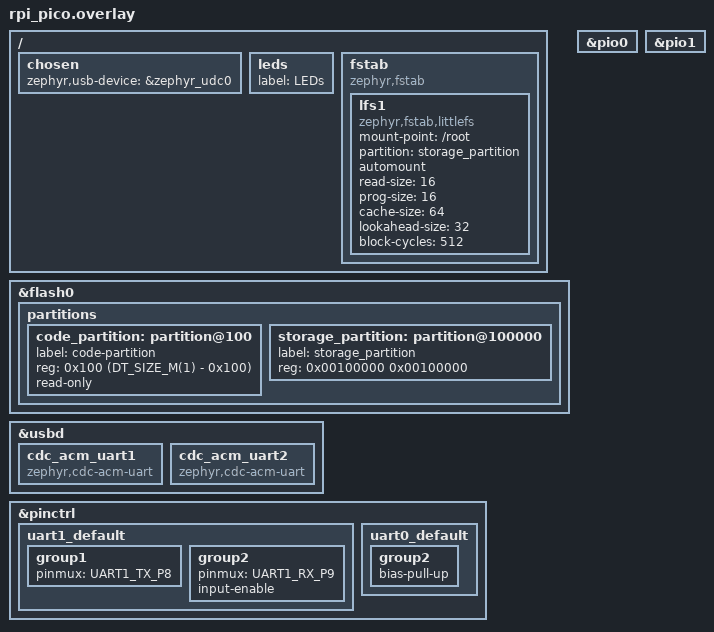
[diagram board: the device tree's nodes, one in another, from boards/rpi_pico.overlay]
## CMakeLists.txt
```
# SPDX-License-Identifier: Apache-2.0

cmake_minimum_required(VERSION 3.20.0)
find_package(Zephyr REQUIRED HINTS $ENV{ZEPHYR_BASE})
project(AllinOneHub)

# target_sources(app PRIVATE boards/gpio_level_raytac_mbt50q_db_40_nrf52840.c)

add_subdirectory(src)
add_subdirectory(lib)
```

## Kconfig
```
# Copyright (c) 2019 Peter Bigot Consulting, LLC
# SPDX-License-Identifier: Apache-2.0

mainmenu "Flower Vending Machine"

config HUB_OFF_TIMEOUT
	int "USB hub off timeout"
	default 1200
	help
	    Timeout to turn off hub power when there is no ping (Unit: seconds)

config HUB_POWER_LED_BLANK_TIME
    int "USB hub power led blank time"
    default 500
    help
        USB hub power led blank time when loss ping (Unit: milliseconds)

config PING_LOSS_DECISION_TIMEOUT
    int "Ping loss decision timeout"
    default 3
    help
        Ping loss decision timeout (Unit: seconds)

config POWER_OFF_SETTING_TIMEOUT
    int "power off setting timeout"
    default 3
    help
        Timeout that automatically comes out of the setting mode 
        when there is no operation when setting the power off schedule
        (Unit: seconds)

rsource "src/Kconfig"
```

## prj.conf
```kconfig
CONFIG_GPIO=y

CONFIG_USB_DEVICE_STACK=y
CONFIG_USB_DEVICE_INITIALIZE_AT_BOOT=n
```

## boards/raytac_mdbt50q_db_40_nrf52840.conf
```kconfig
CONFIG_USB_COMPOSITE_DEVICE=y

# CONFIG_USB_DEVICE_PRODUCT="Zephyr HID and CDC ACM sample"
# CONFIG_USB_DEVICE_PID=0x0003

CONFIG_ENTROPY_GENERATOR=y
CONFIG_ENTROPY_DEVICE_RANDOM_GENERATOR=y

# CONFIG_USB_DEVICE_INITIALIZE_AT_BOOT=n
CONFIG_LOG=y
CONFIG_USB_DRIVER_LOG_LEVEL_INF=y
CONFIG_USB_DEVICE_LOG_LEVEL_INF=y
CONFIG_USB_CDC_ACM_LOG_LEVEL_OFF=y

CONFIG_SERIAL=y
CONFIG_UART_LINE_CTRL=y

# Logging Setting
CONFIG_LOG=y
CONFIG_LOG_BACKEND_UART=y
CONFIG_LOG_BUFFER_SIZE=2048
# CONFIG_LOG_PROCESS_THREAD_STACK_SIZE=4096

# Enable Shell
CONFIG_SHELL=y
CONFIG_SHELL_BACKEND_SERIAL=y
CONFIG_SHELL_LOG_BACKEND=n
CONFIG_SHELL_STACK_SIZE=3168
CONFIG_FILE_SYSTEM_SHELL=y

CONFIG_SYSTEM_WORKQUEUE_STACK_SIZE=4096

# Enable REBOOT
CONFIG_REBOOT=y

# Enable Posix Api
CONFIG_POSIX_API=y
CONFIG_POSIX_FS=y

# Enable c++
CONFIG_CPLUSPLUS=y
CONFIG_CPP_MAIN=y
CONFIG_LIB_CPLUSPLUS=y
# CONFIG_LIBCPP_IMPLEMENTATION=y
CONFIG_HEAP_MEM_POOL_SIZE=10240

CONFIG_MAIN_STACK_SIZE=4096

# Enable I2C
CONFIG_I2C=y

# Enable LED api
CONFIG_LED=y
CONFIG_LED_SHELL=y
```

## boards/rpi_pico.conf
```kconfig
CONFIG_USB_DEVICE_STACK=y
CONFIG_USB_DEVICE_INITIALIZE_AT_BOOT=n
CONFIG_USB_COMPOSITE_DEVICE=y
CONFIG_USB_DEVICE_MANUFACTURER="Superfect"
CONFIG_USB_DEVICE_PRODUCT="AllinOne Monitor Stand"
CONFIG_USB_DEVICE_VID=0x4321
CONFIG_USB_DEVICE_PID=0x0001
CONFIG_USB_DEVICE_REMOTE_WAKEUP=y
CONFIG_USB_DEVICE_HID=y
CONFIG_USB_HID_DEVICE_COUNT=1


# CONFIG_USB_DEVICE_INITIALIZE_AT_BOOT=n
# CONFIG_USB_DRIVER_LOG_LEVEL_INF=y
# CONFIG_USB_DEVICE_LOG_LEVEL_INF=y
# CONFIG_USB_CDC_ACM_LOG_LEVEL_DBG=y
# CONFIG_USB_CDC_ACM_LOG_LEVEL_OFF=y

CONFIG_SERIAL=y
CONFIG_UART_LINE_CTRL=y

# Logging Setting
CONFIG_LOG=y
CONFIG_LOG_BACKEND_UART=y
CONFIG_LOG_BUFFER_SIZE=2048
# CONFIG_LOG_PROCESS_THREAD_STACK_SIZE=4096

# Enable Shell
CONFIG_SHELL=y
CONFIG_SHELL_BACKEND_SERIAL=y
CONFIG_SHELL_BACKEND_DUMMY=y
CONFIG_SHELL_LOG_BACKEND=n
CONFIG_SHELL_STACK_SIZE=3168
CONFIG_FILE_SYSTEM_SHELL=y

CONFIG_SYSTEM_WORKQUEUE_STACK_SIZE=4096

# Enable REBOOT
CONFIG_REBOOT=y

# Enable Flash
CONFIG_FLASH=y
CONFIG_FLASH_MAP=y
CONFIG_FLASH_PAGE_LAYOUT=y
CONFIG_FILE_SYSTEM=y
CONFIG_FILE_SYSTEM_LITTLEFS=y

# Enable Posix Api
CONFIG_POSIX_API=y
CONFIG_POSIX_FS=y

# Enable c++
CONFIG_CPLUSPLUS=y
CONFIG_CPP_MAIN=y
CONFIG_LIB_CPLUSPLUS=y
# CONFIG_LIBCPP_IMPLEMENTATION=y
CONFIG_HEAP_MEM_POOL_SIZE=10240

CONFIG_MAIN_STACK_SIZE=4096

# # Enable I2C
# CONFIG_I2C=y

# Enable LED api
CONFIG_LED=y
CONFIG_LED_SHELL=y

# Enable pio
CONFIG_PIO_RPI_PICO=y

# # Chagnge shell priority
# CONFIG_SHELL_THREAD_PRIORITY_OVERRIDE=y
# CONFIG_SHELL_THREAD_PRIORITY=10

# # Thread analyzer
# CONFIG_THREAD_ANALYZER=y
# CONFIG_THREAD_ANALYZER_AUTO=y

CONFIG_DEBUG_INFO=y
CONFIG_DEBUG_COREDUMP=y
CONFIG_DEBUG_COREDUMP_BACKEND_LOGGING=y
```

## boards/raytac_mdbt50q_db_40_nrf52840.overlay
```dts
/*
 * Copyright (c) 2021 Nordic Semiconductor ASA
 *
 * SPDX-License-Identifier: Apache-2.0
 */

// /delete-node/ &uart1;
// /delete-node/ &uart1_default;
// /delete-node/ &uart1_sleep;

/delete-node/ &i2c1;
/delete-node/ &i2c1_default;
/delete-node/ &i2c1_sleep;

// /delete-node/ &pwm_led0;
// /delete-node/ &pwm0;
// /delete-node/ &pwm0_default;
// /delete-node/ &pwm0_sleep;

/delete-node/ &spi0;
/delete-node/ &spi0_default;
/delete-node/ &spi0_sleep;

/delete-node/ &spi1;
/delete-node/ &spi1_default;
/delete-node/ &spi1_sleep;

/delete-node/ &spi2;
/delete-node/ &spi2_default;
/delete-node/ &spi2_sleep;

/delete-node/ &qspi;
/delete-node/ &qspi_default;
/delete-node/ &qspi_sleep;


/ {
	chosen {
		zephyr,console = &cdc_acm_uart0;
		zephyr,shell-uart = &cdc_acm_uart0;
		zephyr,uart-mcumgr = &cdc_acm_uart0;
		zephyr,bt-mon-uart = &cdc_acm_uart0;
		zephyr,bt-c2h-uart = &cdc_acm_uart0;
        zephyr,usb-device = &zephyr_udc0;
	};

	leds: leds {
		label = "LEDs";
	};
};

&i2c0 {
	clock-frequency = <I2C_BITRATE_STANDARD>;
};

zephyr_udc0: &usbd {
	cdc_acm_uart0: cdc_acm_uart0 {
		compatible = "zephyr,cdc-acm-uart";
	};

	cdc_acm_uart1: cdc_acm_uart1 {
		compatible = "zephyr,cdc-acm-uart";
	};

	// cdc_acm_uart2: cdc_acm_uart2 {
	// 	compatible = "zephyr,cdc-acm-uart";
	// };
};

&pinctrl {
	// i2c0_default: i2c0_default {
	// 	group1 {
	// 		psels = <NRF_PSEL(TWIM_SDA, 0, 22)>,
	// 			<NRF_PSEL(TWIM_SCL, 0, 24)>;
	// 	};
	// };

	// i2c0_sleep: i2c0_sleep {
	// 	group1 {
	// 		psels = <NRF_PSEL(TWIM_SDA, 0, 22)>,
	// 			<NRF_PSEL(TWIM_SCL, 0, 24)>;
	// 		low-power-enable;
	// 	};
	// };
};
```

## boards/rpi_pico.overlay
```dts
/delete-node/ &i2c0;
/delete-node/ &i2c0_default;

/delete-node/ &spi0;
/delete-node/ &spi0_default;

/ {
	chosen {
		// zephyr,console = &cdc_acm_uart0;
		// zephyr,shell-uart = &cdc_acm_uart0;
        zephyr,usb-device = &zephyr_udc0;
	};

	leds: leds {
		label = "LEDs";
	};

	fstab {
		compatible = "zephyr,fstab";
		lfs1: lfs1 {
			compatible = "zephyr,fstab,littlefs";
			mount-point = "/root";
			partition = <&storage_partition>;
			automount;
			read-size = <16>;
			prog-size = <16>;
			cache-size = <64>;
			lookahead-size = <32>;
			block-cycles = <512>;
		};
	};
};

// &uart1 {
// 	current-speed = <9600>;
// 	status = "okay";
// 	pinctrl-0 = <&uart1_default>;
// 	pinctrl-names = "default";
// };

&flash0 {

	partitions {
		/*
		 * Usable flash. Starts at 0x100, after the bootloader. The partition
		 * size is 2MB minus the 0x100 bytes taken by the bootloader.
		 */
		code_partition: partition@100 {
			label = "code-partition";
			reg = <0x100 (DT_SIZE_M(1) - 0x100)>;
			read-only;
		};
		storage_partition: partition@100000 {
			label = "storage_partition";
			reg = <0x00100000 0x00100000>;
		};
	};
};

zephyr_udc0: &usbd {
	// cdc_acm_uart0: cdc_acm_uart0 {
	// 	compatible = "zephyr,cdc-acm-uart";
	// };

	cdc_acm_uart1: cdc_acm_uart1 {
		compatible = "zephyr,cdc-acm-uart";
	};

	cdc_acm_uart2: cdc_acm_uart2 {
		compatible = "zephyr,cdc-acm-uart";
	};
};

&pio0 {
	status = "okay";
};

&pio1 {
	status = "okay";
};

&pinctrl {
	uart1_default: uart1_default {
		group1 {
			pinmux = <UART1_TX_P8>;
		};
		group2 {
			pinmux = <UART1_RX_P9>;
			input-enable;
		};
	};
	uart0_default: uart0_default {
		group2 {
			bias-pull-up;
		};
	};
};
```

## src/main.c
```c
/*
 * Copyright (c) 2018 Intel Corporation
 *
 * SPDX-License-Identifier: Apache-2.0
 */

#include <zephyr/kernel.h>
#include <zephyr/sys/printk.h>
#include <zephyr/usb/usb_device.h>
#include <zephyr/usb/usbd.h>
#include <zephyr/drivers/uart.h>

#include <zephyr/logging/log.h>

LOG_MODULE_REGISTER(main);

int main(void)
{
    int ret = usb_enable(NULL);
	if (ret != 0) {
		return -1;
	}

    LOG_INF("Start All in one hub");


    while(true) {
        LOG_INF("Test Loging");
        k_msleep(1000);
    }

    return 0;
}
```

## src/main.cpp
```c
/*
 * Copyright (c) 2018 Intel Corporation
 *
 * SPDX-License-Identifier: Apache-2.0
 */

#include <zephyr/kernel.h>
#include <zephyr/sys/printk.h>
#include <zephyr/usb/usb_device.h>
#include <zephyr/usb/usbd.h>
#include <zephyr/drivers/uart.h>
#include <zephyr/usb/class/usb_hid.h>

#include <Controller.h>

#include <zephyr/logging/log.h>
LOG_MODULE_REGISTER(main);

static const uint8_t hid_kbd_report_desc[] = HID_KEYBOARD_REPORT_DESC();

static void status_cb(enum usb_dc_status_code status, const uint8_t *param)
{
	Controller* ctrl = Controller::getInstance();
	ctrl->_usb_status = status;
}

int main(void)
{
	usb_hid_register_device(device_get_binding("HID_0"), hid_kbd_report_desc,
				sizeof(hid_kbd_report_desc), NULL);
	usb_hid_init(device_get_binding("HID_0"));
	int ret = usb_enable(status_cb);
	if (ret != 0) {
		return -1;
	}

    LOG_INF("Start All in one hub");

	Controller* ctrl = Controller::getInstance();
	ctrl->setup();

    while(true) {
        ctrl->loop();
    }

    return 0;
}
```
